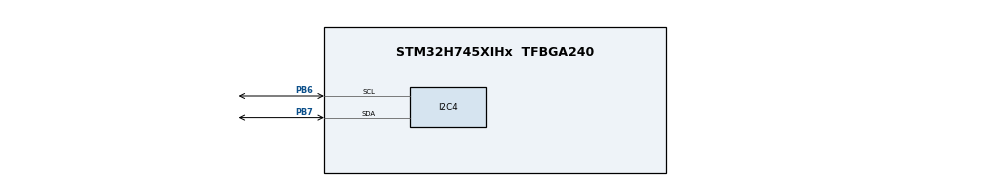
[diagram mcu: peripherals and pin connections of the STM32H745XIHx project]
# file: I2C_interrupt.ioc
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CortexM4.IPs=FATFS_M4\:I,FREERTOS_M4\:I,IWDG2\:I,RCC,USB_DEVICE_M4\:I,USB_HOST_M4\:I,WWDG2\:I,DMA,BDMA,MDMA,NVIC2\:I,ETH\:I,FDCAN1\:I,FDCAN2\:I,FMC\:I,QUADSPI\:I,SAI2\:I,SDMMC1\:I,USART3\:I,LTDC\:I,USB_OTG_FS\:I,SAI4\:I,DEBUG,PDM2PCM_M4\:I,PWR,RESMGR_UTILITY,SYS_M4\:I,CORTEX_M4\:I,OPENAMP_M4\:I,VREFBUF
CortexM7.IPs=FATFS_M7\:I,FREERTOS_M7\:I,IWDG1\:I,RCC\:I,USB_DEVICE_M7\:I,USB_HOST_M7\:I,WWDG1\:I,DMA\:I,BDMA\:I,MDMA\:I,NVIC1\:I,CORTEX_M7\:I,DEBUG\:I,PDM2PCM_M7\:I,PWR\:I,RESMGR_UTILITY\:I,SYS\:I,OPENAMP_M7\:I,VREFBUF\:I,I2C4\:I
I2C4.OwnAddress=0x040
I2C4.Timing=0x10C0ECFF
Mcu.Family=STM32H7
Mcu.Name=STM32H745XIHx
Mcu.Package=TFBGA240
NVIC1.PriorityGroup=NVIC_PRIORITYGROUP_4
NVIC2.PriorityGroup=NVIC_PRIORITYGROUP_4
PB6.Mode=I2C
PB6.PinAttribute=CortexM7
PB6.Signal=I2C4_SCL
PB7.Mode=I2C
PB7.PinAttribute=CortexM7
PB7.Signal=I2C4_SDA
PH0-OSC_IN\ (PH0).Mode=HSE-External-Clock-Source
PH0-OSC_IN\ (PH0).PinAttribute=CortexM7
PH0-OSC_IN\ (PH0).Signal=RCC_OSC_IN
ProjectManager.HeapSize=M4-0x200,M7-0x200
ProjectManager.StackSize=M4-0x400,M7-0x400
ProjectManager.TargetToolchain=STM32CubeIDE
RCC.ADCFreq_Value=50390625
RCC.APB1Freq_Value=100000000
RCC.APB2Freq_Value=100000000
RCC.APB3Freq_Value=100000000
RCC.APB4Freq_Value=100000000
RCC.CortexFreq_Value=400000000
RCC.D1PPRE=RCC_APB3_DIV2
RCC.D2PPRE1=RCC_APB1_DIV2
RCC.D2PPRE2=RCC_APB2_DIV2
RCC.D3PPRE=RCC_APB4_DIV2
RCC.DIVM1=5
RCC.DIVN1=160
RCC.DIVN3=192
RCC.DIVQ1=4
RCC.DIVR1=4
RCC.HCLKFreq_Value=200000000
RCC.HPRE=RCC_HCLK_DIV2
RCC.PLL2FRACN=0
RCC.PLL3FRACN=0
RCC.PLLFRACN=0
RCC.PLLSourceVirtual=RCC_PLLSOURCE_HSE
RCC.PWR_Regulator_Voltage_Scale=PWR_REGULATOR_VOLTAGE_SCALE1
RCC.SYSCLKFreq_VALUE=400000000
RCC.SYSCLKSource=RCC_SYSCLKSOURCE_PLLCLK
RCC.SupplySource=PWR_DIRECT_SMPS_SUPPLY
RCC.USBFreq_Value=200000000
VP_SYS_M4_VS_Systick.Mode=SysTick
board=STM32H745I-DISCO

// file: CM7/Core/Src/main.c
/* USER CODE BEGIN Header */
/**
  ******************************************************************************
  * @file           : main.c
  * @brief          : Main program body
  ******************************************************************************
  * @attention
  *
  * <h2><center>&copy; Copyright (c) 2022 STMicroelectronics.
  * All rights reserved.</center></h2>
  *
  * This software component is licensed by ST under BSD 3-Clause license,
  * the "License"; You may not use this file except in compliance with the
  * License. You may obtain a copy of the License at:
  *                        opensource.org/licenses/BSD-3-Clause
  *
  ******************************************************************************
  */
/* USER CODE END Header */
#include "main.h"

/* USER CODE BEGIN PD */

#ifndef HSEM_ID_0
#define HSEM_ID_0 (0U) /* HW semaphore 0*/
#endif
/* USER CODE END PD */

I2C_HandleTypeDef hi2c4;

void SystemClock_Config(void);
static void MX_GPIO_Init(void);
static void MX_I2C4_Init(void);

/* USER CODE BEGIN 0 */
uint8_t DevMem = 0x40<<1;
/* USER CODE END 0 */

int main(void)
{
/* USER CODE BEGIN Boot_Mode_Sequence_0 */
//  int32_t timeout;
/* USER CODE END Boot_Mode_Sequence_0 */

/* USER CODE BEGIN Boot_Mode_Sequence_1 */
  /* Wait until CPU2 boots and enters in stop mode or timeout*/
//  timeout = 0xFFFF;
//  while((__HAL_RCC_GET_FLAG(RCC_FLAG_D2CKRDY) != RESET) && (timeout-- > 0));
//  if ( timeout < 0 )
//  {
//  Error_Handler();
//  }
/* USER CODE END Boot_Mode_Sequence_1 */
  /* MCU Configuration--------------------------------------------------------*/

  /* Reset of all peripherals, Initializes the Flash interface and the Systick. */
  HAL_Init();

  /* Configure the system clock */
  SystemClock_Config();
/* USER CODE BEGIN Boot_Mode_Sequence_2 */
/* When system initialization is finished, Cortex-M7 will release Cortex-M4 by means of
HSEM notification */
/*HW semaphore Clock enable*/
//__HAL_RCC_HSEM_CLK_ENABLE();
///*Take HSEM */
//HAL_HSEM_FastTake(HSEM_ID_0);
///*Release HSEM in order to notify the CPU2(CM4)*/
//HAL_HSEM_Release(HSEM_ID_0,0);
///* wait until CPU2 wakes up from stop mode */
//timeout = 0xFFFF;
//while((__HAL_RCC_GET_FLAG(RCC_FLAG_D2CKRDY) == RESET) && (timeout-- > 0));
//if ( timeout < 0 )
//{
//Error_Handler();
//}
/* USER CODE END Boot_Mode_Sequence_2 */

  /* Initialize all configured peripherals */
  MX_GPIO_Init();
  MX_I2C4_Init();

  /* Infinite loop */
  while (1)
  {

  }
}

void SystemClock_Config(void)
{
  RCC_OscInitTypeDef RCC_OscInitStruct = {0};
  RCC_ClkInitTypeDef RCC_ClkInitStruct = {0};

  /** Supply configuration update enable
  */
  HAL_PWREx_ConfigSupply(PWR_DIRECT_SMPS_SUPPLY);
  /** Configure the main internal regulator output voltage
  */
  __HAL_PWR_VOLTAGESCALING_CONFIG(PWR_REGULATOR_VOLTAGE_SCALE1);

  while(!__HAL_PWR_GET_FLAG(PWR_FLAG_VOSRDY)) {}
  /** Initializes the RCC Oscillators according to the specified parameters
  * in the RCC_OscInitTypeDef structure.
  */
  RCC_OscInitStruct.OscillatorType = RCC_OSCILLATORTYPE_HSE;
  RCC_OscInitStruct.HSEState = RCC_HSE_BYPASS;
  RCC_OscInitStruct.PLL.PLLState = RCC_PLL_ON;
  RCC_OscInitStruct.PLL.PLLSource = RCC_PLLSOURCE_HSE;
  RCC_OscInitStruct.PLL.PLLM = 5;
  RCC_OscInitStruct.PLL.PLLN = 160;
  RCC_OscInitStruct.PLL.PLLP = 2;
  RCC_OscInitStruct.PLL.PLLQ = 4;
  RCC_OscInitStruct.PLL.PLLR = 4;
  RCC_OscInitStruct.PLL.PLLRGE = RCC_PLL1VCIRANGE_2;
  RCC_OscInitStruct.PLL.PLLVCOSEL = RCC_PLL1VCOWIDE;
  RCC_OscInitStruct.PLL.PLLFRACN = 0;
  if (HAL_RCC_OscConfig(&RCC_OscInitStruct) != HAL_OK)
  {
    Error_Handler();
  }
  /** Initializes the CPU, AHB and APB buses clocks
  */
  RCC_ClkInitStruct.ClockType = RCC_CLOCKTYPE_HCLK|RCC_CLOCKTYPE_SYSCLK
                              |RCC_CLOCKTYPE_PCLK1|RCC_CLOCKTYPE_PCLK2
                              |RCC_CLOCKTYPE_D3PCLK1|RCC_CLOCKTYPE_D1PCLK1;
  RCC_ClkInitStruct.SYSCLKSource = RCC_SYSCLKSOURCE_PLLCLK;
  RCC_ClkInitStruct.SYSCLKDivider = RCC_SYSCLK_DIV1;
  RCC_ClkInitStruct.AHBCLKDivider = RCC_HCLK_DIV2;
  RCC_ClkInitStruct.APB3CLKDivider = RCC_APB3_DIV2;
  RCC_ClkInitStruct.APB1CLKDivider = RCC_APB1_DIV2;
  RCC_ClkInitStruct.APB2CLKDivider = RCC_APB2_DIV2;
  RCC_ClkInitStruct.APB4CLKDivider = RCC_APB4_DIV2;

  if (HAL_RCC_ClockConfig(&RCC_ClkInitStruct, FLASH_LATENCY_2) != HAL_OK)
  {
    Error_Handler();
  }
}

static void MX_I2C4_Init(void)
{

  hi2c4.Instance = I2C4;
  hi2c4.Init.Timing = 0x10C0ECFF;
  hi2c4.Init.OwnAddress1 = 128;
  hi2c4.Init.AddressingMode = I2C_ADDRESSINGMODE_7BIT;
  hi2c4.Init.DualAddressMode = I2C_DUALADDRESS_DISABLE;
  hi2c4.Init.OwnAddress2 = 0;
  hi2c4.Init.OwnAddress2Masks = I2C_OA2_NOMASK;
  hi2c4.Init.GeneralCallMode = I2C_GENERALCALL_DISABLE;
  hi2c4.Init.NoStretchMode = I2C_NOSTRETCH_DISABLE;
  if (HAL_I2C_Init(&hi2c4) != HAL_OK)
  {
    Error_Handler();
  }
  /** Configure Analogue filter
  */
  if (HAL_I2CEx_ConfigAnalogFilter(&hi2c4, I2C_ANALOGFILTER_ENABLE) != HAL_OK)
  {
    Error_Handler();
  }
  /** Configure Digital filter
  */
  if (HAL_I2CEx_ConfigDigitalFilter(&hi2c4, 0) != HAL_OK)
  {
    Error_Handler();
  }

}

static void MX_GPIO_Init(void)
{

  /* GPIO Ports Clock Enable */
  __HAL_RCC_GPIOB_CLK_ENABLE();
  __HAL_RCC_GPIOH_CLK_ENABLE();

}

void Error_Handler(void)
{
  __disable_irq();
  while (1)
  {
  }
}

/************************ (C) COPYRIGHT STMicroelectronics *****END OF FILE****/
